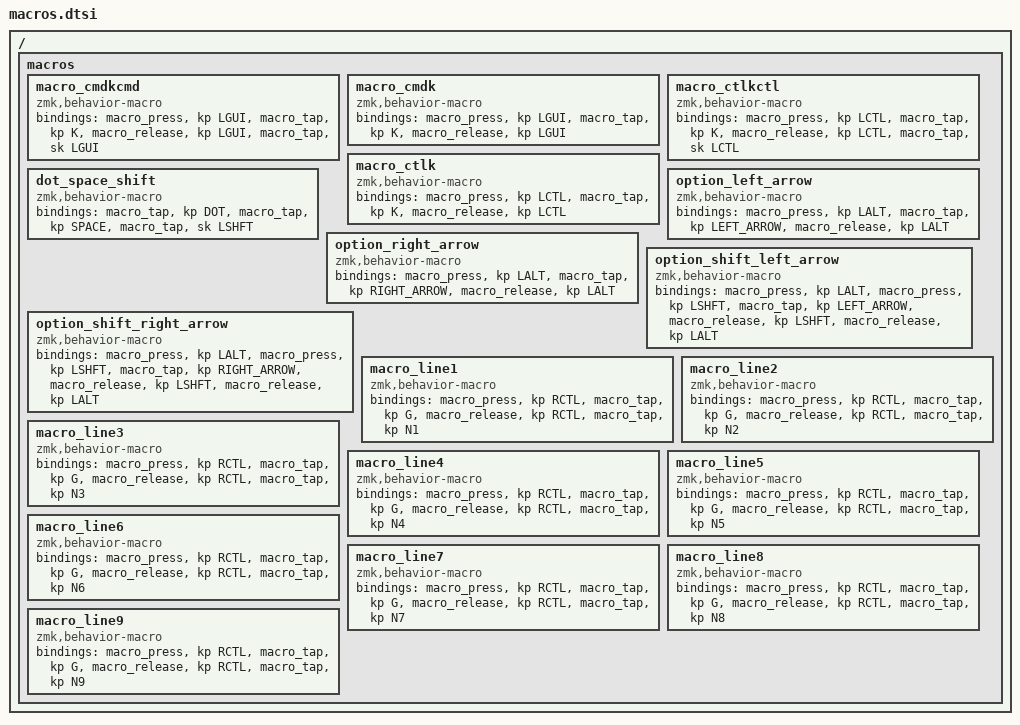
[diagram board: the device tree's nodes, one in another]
/ {
    macros {
        macro_cmdkcmd: macro_cmdkcmd {
            compatible = "zmk,behavior-macro";
            #binding-cells = <0>;
            bindings
                = <&macro_press &kp LGUI>
                , <&macro_tap &kp K>
                , <&macro_release &kp LGUI>
                , <&macro_tap &sk LGUI>
                ;
        };
        macro_cmdk: macro_cmdk {
            compatible = "zmk,behavior-macro";
            #binding-cells = <0>;
            bindings
                = <&macro_press &kp LGUI>
                , <&macro_tap &kp K>
                , <&macro_release &kp LGUI>
                ;
        };
        macro_ctlkctl: macro_ctlkctl {
            compatible = "zmk,behavior-macro";
            #binding-cells = <0>;
            bindings
                = <&macro_press &kp LCTL>
                , <&macro_tap &kp K>
                , <&macro_release &kp LCTL>
                , <&macro_tap &sk LCTL>
                ;
        };
        macro_ctlk: macro_ctlk {
            compatible = "zmk,behavior-macro";
            #binding-cells = <0>;
            bindings
                = <&macro_press &kp LCTL>
                , <&macro_tap &kp K>
                , <&macro_release &kp LCTL>
                ;
        };
        dot_space_shift: dot_space_shift {
            compatible = "zmk,behavior-macro";
            #binding-cells = <0>;
            bindings
                = <&macro_tap &kp DOT>
                , <&macro_tap &kp SPACE>
                , <&macro_tap &sk LSHFT>
                ;
        };
        option_left_arrow: option_left_arrow {
            compatible = "zmk,behavior-macro";
            #binding-cells = <0>;
            bindings
                = <&macro_press &kp LALT>
                , <&macro_tap &kp LEFT_ARROW>
                , <&macro_release &kp LALT>
                ;
        };
        option_right_arrow: option_right_arrow {
            compatible = "zmk,behavior-macro";
            #binding-cells = <0>;
            bindings
                = <&macro_press &kp LALT>
                , <&macro_tap &kp RIGHT_ARROW>
                , <&macro_release &kp LALT>
                ;
        };
         option_shift_left_arrow: option_shift_left_arrow {
            compatible = "zmk,behavior-macro";
            #binding-cells = <0>;
            bindings
                = <&macro_press &kp LALT>
                , <&macro_press &kp LSHFT>
                , <&macro_tap &kp LEFT_ARROW>
                , <&macro_release &kp LSHFT>
                , <&macro_release &kp LALT>
                ;
        };
        option_shift_right_arrow: option_shift_right_arrow {
            compatible = "zmk,behavior-macro";
            #binding-cells = <0>;
            bindings
                = <&macro_press &kp LALT>
                , <&macro_press &kp LSHFT>
                , <&macro_tap &kp RIGHT_ARROW>
                , <&macro_release &kp LSHFT>
                , <&macro_release &kp LALT>
                ;
        };
        macro_line1: macro_line1 {
            compatible = "zmk,behavior-macro";
            #binding-cells = <0>;
            bindings
                = <&macro_press &kp RCTL>
                , <&macro_tap &kp G>
                , <&macro_release &kp RCTL>
                , <&macro_tap &kp N1>
                ;
        };
        macro_line2: macro_line2 {
            compatible = "zmk,behavior-macro";
            #binding-cells = <0>;
            bindings
                = <&macro_press &kp RCTL>
                , <&macro_tap &kp G>
                , <&macro_release &kp RCTL>
                , <&macro_tap &kp N2>
                ;
        };
        macro_line3: macro_line3 {
            compatible = "zmk,behavior-macro";
            #binding-cells = <0>;
            bindings
                = <&macro_press &kp RCTL>
                , <&macro_tap &kp G>
                , <&macro_release &kp RCTL>
                , <&macro_tap &kp N3>
                ;
        };
        macro_line4: macro_line4 {
            compatible = "zmk,behavior-macro";
            #binding-cells = <0>;
            bindings
                = <&macro_press &kp RCTL>
                , <&macro_tap &kp G>
                , <&macro_release &kp RCTL>
                , <&macro_tap &kp N4>
                ;
        };
        macro_line5: macro_line5 {
            compatible = "zmk,behavior-macro";
            #binding-cells = <0>;
            bindings
                = <&macro_press &kp RCTL>
                , <&macro_tap &kp G>
                , <&macro_release &kp RCTL>
                , <&macro_tap &kp N5>
                ;
        };
        macro_line6: macro_line6 {
            compatible = "zmk,behavior-macro";
            #binding-cells = <0>;
            bindings
                = <&macro_press &kp RCTL>
                , <&macro_tap &kp G>
                , <&macro_release &kp RCTL>
                , <&macro_tap &kp N6>
                ;
        };
        macro_line7: macro_line7 {
            compatible = "zmk,behavior-macro";
            #binding-cells = <0>;
            bindings
                = <&macro_press &kp RCTL>
                , <&macro_tap &kp G>
                , <&macro_release &kp RCTL>
                , <&macro_tap &kp N7>
                ;
        };
        macro_line8: macro_line8 {
            compatible = "zmk,behavior-macro";
            #binding-cells = <0>;
            bindings
                = <&macro_press &kp RCTL>
                , <&macro_tap &kp G>
                , <&macro_release &kp RCTL>
                , <&macro_tap &kp N8>
                ;
        };
        macro_line9: macro_line9 {
            compatible = "zmk,behavior-macro";
            #binding-cells = <0>;
            bindings
                = <&macro_press &kp RCTL>
                , <&macro_tap &kp G>
                , <&macro_release &kp RCTL>
                , <&macro_tap &kp N9>
                ;
        };
    };
};                                  

